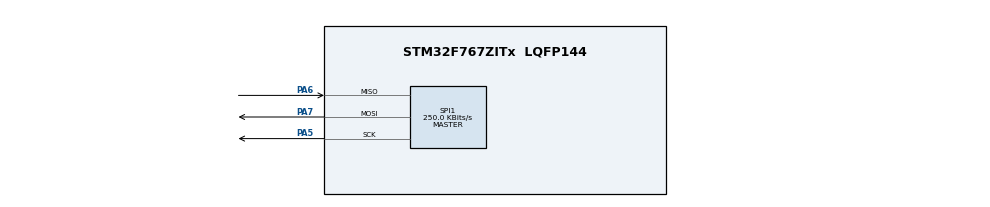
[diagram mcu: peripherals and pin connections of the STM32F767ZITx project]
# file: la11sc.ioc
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CORTEX_M7.default_mode_Activation=1
Dma.Request0=SPI1_RX
Dma.Request1=SPI1_TX
Dma.SPI1_RX.0.Direction=DMA_PERIPH_TO_MEMORY
Dma.SPI1_RX.0.FIFOMode=DMA_FIFOMODE_DISABLE
Dma.SPI1_RX.0.Instance=DMA2_Stream0
Dma.SPI1_RX.0.MemDataAlignment=DMA_MDATAALIGN_HALFWORD
Dma.SPI1_RX.0.MemInc=DMA_MINC_ENABLE
Dma.SPI1_RX.0.Mode=DMA_NORMAL
Dma.SPI1_RX.0.PeriphDataAlignment=DMA_PDATAALIGN_HALFWORD
Dma.SPI1_RX.0.PeriphInc=DMA_PINC_DISABLE
Dma.SPI1_RX.0.Priority=DMA_PRIORITY_LOW
Dma.SPI1_TX.1.Direction=DMA_MEMORY_TO_PERIPH
Dma.SPI1_TX.1.FIFOMode=DMA_FIFOMODE_DISABLE
Dma.SPI1_TX.1.Instance=DMA2_Stream3
Dma.SPI1_TX.1.MemDataAlignment=DMA_MDATAALIGN_HALFWORD
Dma.SPI1_TX.1.MemInc=DMA_MINC_ENABLE
Dma.SPI1_TX.1.Mode=DMA_NORMAL
Dma.SPI1_TX.1.PeriphDataAlignment=DMA_PDATAALIGN_HALFWORD
Dma.SPI1_TX.1.PeriphInc=DMA_PINC_DISABLE
Dma.SPI1_TX.1.Priority=DMA_PRIORITY_LOW
Mcu.Family=STM32F7
Mcu.Name=STM32F767ZITx
Mcu.Package=LQFP144
NVIC.DMA2_Stream0_IRQn=true\:0\:0\:false\:false\:true\:false\:true\:true
NVIC.DMA2_Stream3_IRQn=true\:0\:0\:false\:false\:true\:false\:true\:true
NVIC.PriorityGroup=NVIC_PRIORITYGROUP_4
NVIC.SPI1_IRQn=true\:0\:0\:false\:false\:true\:true\:true\:true
NVIC.TIM1_UP_TIM10_IRQn=true\:0\:0\:false\:false\:true\:true\:true\:true
PA5.Mode=Full_Duplex_Master
PA5.Signal=SPI1_SCK
PA6.Mode=Full_Duplex_Master
PA6.Signal=SPI1_MISO
PA7.Mode=Full_Duplex_Master
PA7.Signal=SPI1_MOSI
ProjectManager.HeapSize=0x200
ProjectManager.StackSize=0x400
ProjectManager.TargetToolchain=STM32CubeIDE
RCC.HSE_VALUE=25000000
RCC.HSI_VALUE=16000000
RCC.LSE_VALUE=32768
RCC.USBFreq_Value=96000000
RCC.VCOOutputFreq_Value=192000000
SPI1.BaudRatePrescaler=SPI_BAUDRATEPRESCALER_64
SPI1.CLKPhase=SPI_PHASE_2EDGE
SPI1.CLKPolarity=SPI_POLARITY_HIGH
SPI1.CalculateBaudRate=250.0 KBits/s
SPI1.DataSize=SPI_DATASIZE_16BIT
SPI1.Direction=SPI_DIRECTION_2LINES
SPI1.Mode=SPI_MODE_MASTER
SPI1.VirtualType=VM_MASTER
TIM10.Period=1000
TIM10.Prescaler=160
VP_TIM10_VS_ClockSourceINT.Mode=Enable_Timer
board=custom

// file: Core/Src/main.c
/* USER CODE BEGIN Header */
/**
  ******************************************************************************
  * @file           : main.c
  * @brief          : Main program body
  ******************************************************************************
  * @attention
  *
  * Copyright (c) 2026 STMicroelectronics.
  * All rights reserved.
  *
  * This software is licensed under terms that can be found in the LICENSE file
  * in the root directory of this software component.
  * If no LICENSE file comes with this software, it is provided AS-IS.
  *
  ******************************************************************************
  */
/* USER CODE END Header */
#include "main.h"

/* USER CODE BEGIN Includes */
#include "encoder_ssi.h"

/* USER CODE END Includes */

SPI_HandleTypeDef hspi1;
DMA_HandleTypeDef hdma_spi1_rx;
DMA_HandleTypeDef hdma_spi1_tx;

TIM_HandleTypeDef htim10;

void SystemClock_Config(void);
static void MPU_Config(void);
static void MX_GPIO_Init(void);
static void MX_DMA_Init(void);
static void MX_SPI1_Init(void);
static void MX_TIM10_Init(void);

int main(void)
{

  /* MPU Configuration--------------------------------------------------------*/
  MPU_Config();

  /* MCU Configuration--------------------------------------------------------*/

  /* Reset of all peripherals, Initializes the Flash interface and the Systick. */
  HAL_Init();

  /* Configure the system clock */
  SystemClock_Config();

  /* Initialize all configured peripherals */
  MX_GPIO_Init();
  MX_DMA_Init();
  MX_SPI1_Init();
  MX_TIM10_Init();
  /* USER CODE BEGIN 2 */
  la11sc_spi_start(&la11sc_encoder);
  HAL_TIM_Base_Start_IT(&htim10);

  /* USER CODE END 2 */

  /* Infinite loop */
  /* USER CODE BEGIN WHILE */
  while (1)
  {
    if (la11sc_encoder.request_read)
    {
      la11sc_spi_read(&la11sc_encoder, &hspi1);
    }
    /* USER CODE END WHILE */

  }
}

void SystemClock_Config(void)
{
  RCC_OscInitTypeDef RCC_OscInitStruct = {0};
  RCC_ClkInitTypeDef RCC_ClkInitStruct = {0};

  /** Configure the main internal regulator output voltage
  */
  __HAL_RCC_PWR_CLK_ENABLE();
  __HAL_PWR_VOLTAGESCALING_CONFIG(PWR_REGULATOR_VOLTAGE_SCALE3);

  /** Initializes the RCC Oscillators according to the specified parameters
  * in the RCC_OscInitTypeDef structure.
  */
  RCC_OscInitStruct.OscillatorType = RCC_OSCILLATORTYPE_HSI;
  RCC_OscInitStruct.HSIState = RCC_HSI_ON;
  RCC_OscInitStruct.HSICalibrationValue = RCC_HSICALIBRATION_DEFAULT;
  RCC_OscInitStruct.PLL.PLLState = RCC_PLL_NONE;
  if (HAL_RCC_OscConfig(&RCC_OscInitStruct) != HAL_OK)
  {
    Error_Handler();
  }

  /** Initializes the CPU, AHB and APB buses clocks
  */
  RCC_ClkInitStruct.ClockType = RCC_CLOCKTYPE_HCLK|RCC_CLOCKTYPE_SYSCLK
                              |RCC_CLOCKTYPE_PCLK1|RCC_CLOCKTYPE_PCLK2;
  RCC_ClkInitStruct.SYSCLKSource = RCC_SYSCLKSOURCE_HSI;
  RCC_ClkInitStruct.AHBCLKDivider = RCC_SYSCLK_DIV1;
  RCC_ClkInitStruct.APB1CLKDivider = RCC_HCLK_DIV1;
  RCC_ClkInitStruct.APB2CLKDivider = RCC_HCLK_DIV1;

  if (HAL_RCC_ClockConfig(&RCC_ClkInitStruct, FLASH_LATENCY_0) != HAL_OK)
  {
    Error_Handler();
  }
}

static void MX_SPI1_Init(void)
{

  /* SPI1 parameter configuration*/
  hspi1.Instance = SPI1;
  hspi1.Init.Mode = SPI_MODE_MASTER;
  hspi1.Init.Direction = SPI_DIRECTION_2LINES;
  hspi1.Init.DataSize = SPI_DATASIZE_16BIT;
  hspi1.Init.CLKPolarity = SPI_POLARITY_HIGH;
  hspi1.Init.CLKPhase = SPI_PHASE_2EDGE;
  hspi1.Init.NSS = SPI_NSS_SOFT;
  hspi1.Init.BaudRatePrescaler = SPI_BAUDRATEPRESCALER_64;
  hspi1.Init.FirstBit = SPI_FIRSTBIT_MSB;
  hspi1.Init.TIMode = SPI_TIMODE_DISABLE;
  hspi1.Init.CRCCalculation = SPI_CRCCALCULATION_DISABLE;
  hspi1.Init.CRCPolynomial = 7;
  hspi1.Init.CRCLength = SPI_CRC_LENGTH_DATASIZE;
  hspi1.Init.NSSPMode = SPI_NSS_PULSE_DISABLE;
  if (HAL_SPI_Init(&hspi1) != HAL_OK)
  {
    Error_Handler();
  }

}

static void MX_TIM10_Init(void)
{

  htim10.Instance = TIM10;
  htim10.Init.Prescaler = 160;
  htim10.Init.CounterMode = TIM_COUNTERMODE_UP;
  htim10.Init.Period = 1000;
  htim10.Init.ClockDivision = TIM_CLOCKDIVISION_DIV1;
  htim10.Init.AutoReloadPreload = TIM_AUTORELOAD_PRELOAD_DISABLE;
  if (HAL_TIM_Base_Init(&htim10) != HAL_OK)
  {
    Error_Handler();
  }

}

static void MX_DMA_Init(void)
{

  /* DMA controller clock enable */
  __HAL_RCC_DMA2_CLK_ENABLE();

  /* DMA interrupt init */
  /* DMA2_Stream0_IRQn interrupt configuration */
  HAL_NVIC_SetPriority(DMA2_Stream0_IRQn, 0, 0);
  HAL_NVIC_EnableIRQ(DMA2_Stream0_IRQn);
  /* DMA2_Stream3_IRQn interrupt configuration */
  HAL_NVIC_SetPriority(DMA2_Stream3_IRQn, 0, 0);
  HAL_NVIC_EnableIRQ(DMA2_Stream3_IRQn);

}

static void MX_GPIO_Init(void)
{

  /* GPIO Ports Clock Enable */
  __HAL_RCC_GPIOA_CLK_ENABLE();

}

/* USER CODE BEGIN 4 */
void HAL_TIM_PeriodElapsedCallback(TIM_HandleTypeDef *htim)
{
  if (htim->Instance == TIM10)
  {
    la11sc_spi_request_read(&la11sc_encoder);
  }
}

void HAL_SPI_TxRxCpltCallback(SPI_HandleTypeDef *hspi)
{
  if (hspi->Instance == SPI1)
  {
    la11sc_spi_irq(&la11sc_encoder);
  }
}

void HAL_SPI_ErrorCallback(SPI_HandleTypeDef *hspi)
{
  if (hspi->Instance == SPI1)
  {
    la11sc_spi_error(&la11sc_encoder);
  }
}

/* USER CODE END 4 */

 /* MPU Configuration */

void MPU_Config(void)
{
  MPU_Region_InitTypeDef MPU_InitStruct = {0};

  /* Disables the MPU */
  HAL_MPU_Disable();

  /** Initializes and configures the Region and the memory to be protected
  */
  MPU_InitStruct.Enable = MPU_REGION_ENABLE;
  MPU_InitStruct.Number = MPU_REGION_NUMBER0;
  MPU_InitStruct.BaseAddress = 0x0;
  MPU_InitStruct.Size = MPU_REGION_SIZE_4GB;
  MPU_InitStruct.SubRegionDisable = 0x87;
  MPU_InitStruct.TypeExtField = MPU_TEX_LEVEL0;
  MPU_InitStruct.AccessPermission = MPU_REGION_NO_ACCESS;
  MPU_InitStruct.DisableExec = MPU_INSTRUCTION_ACCESS_DISABLE;
  MPU_InitStruct.IsShareable = MPU_ACCESS_SHAREABLE;
  MPU_InitStruct.IsCacheable = MPU_ACCESS_NOT_CACHEABLE;
  MPU_InitStruct.IsBufferable = MPU_ACCESS_NOT_BUFFERABLE;

  HAL_MPU_ConfigRegion(&MPU_InitStruct);
  /* Enables the MPU */
  HAL_MPU_Enable(MPU_PRIVILEGED_DEFAULT);

}

void Error_Handler(void)
{
  __disable_irq();
  while (1)
  {
  }
}
